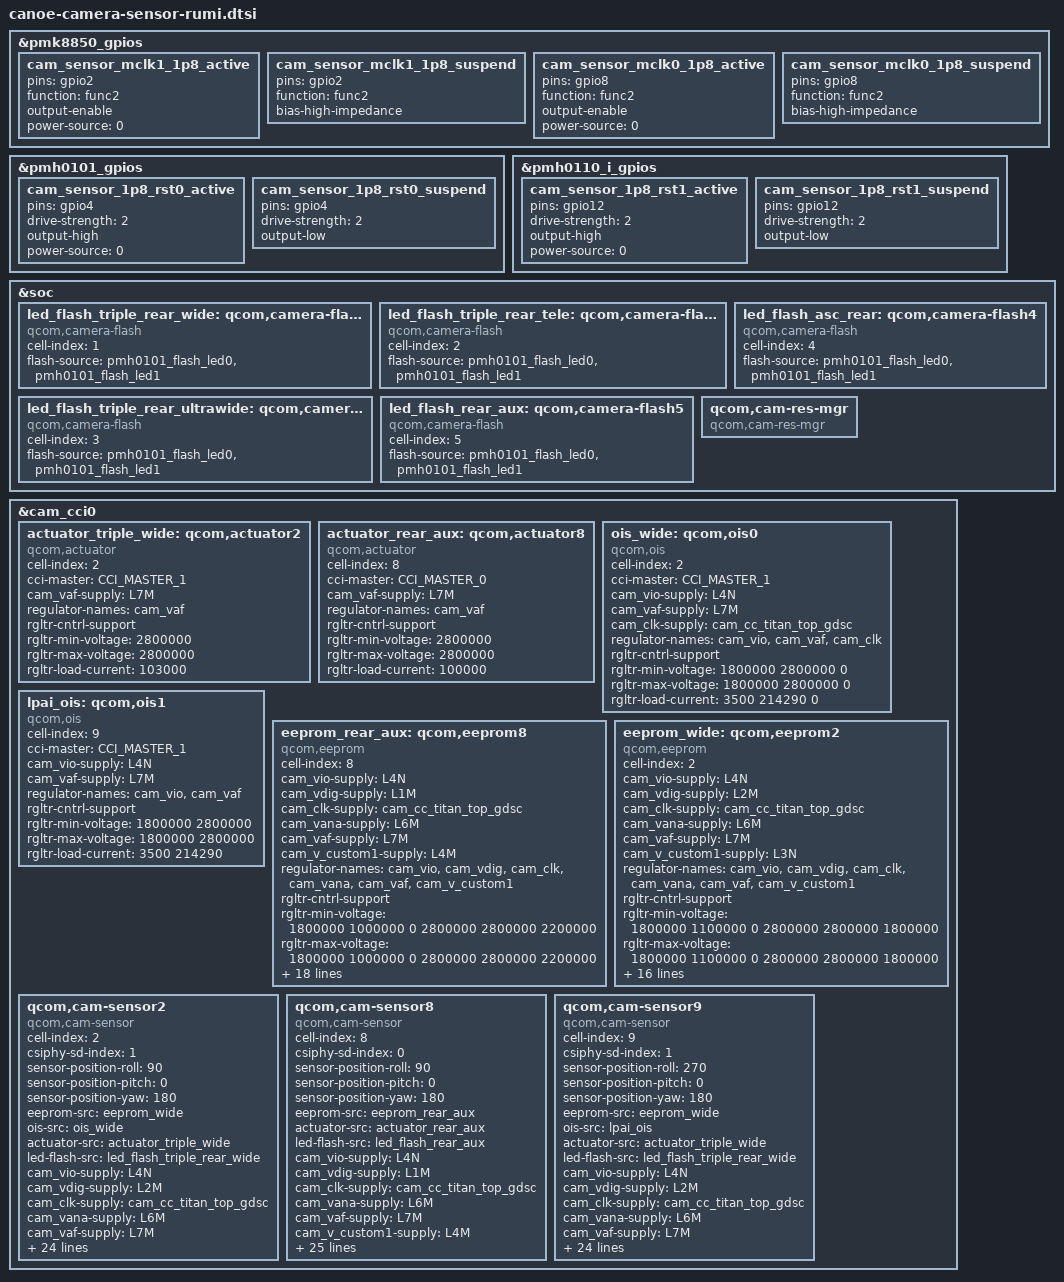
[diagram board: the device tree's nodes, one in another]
// SPDX-License-Identifier: BSD-3-Clause
/*
 * Copyright (c) 2024 Qualcomm Innovation Center, Inc. All rights reserved.
 */

#include <dt-bindings/msm-camera.h>

&pmk8850_gpios {
	cam_sensor_mclk1_1p8_active: cam_sensor_mclk1_1p8_active {
			pins = "gpio2";
			function = "func2";
			output-enable;
			power-source = <0>; /* 1.8 V */
	};

	cam_sensor_mclk1_1p8_suspend: cam_sensor_mclk1_1p8_suspend {
			pins = "gpio2";
			function = "func2";
			bias-high-impedance;
	};

	cam_sensor_mclk0_1p8_active: cam_sensor_mclk0_1p8_active {
			pins = "gpio8";
			function = "func2";
			output-enable;
			power-source = <0>; /* 1.8 V */
	};

	cam_sensor_mclk0_1p8_suspend: cam_sensor_mclk0_1p8_suspend {
			pins = "gpio8";
			function = "func2";
			bias-high-impedance;
	};
};

&pmh0101_gpios {
	cam_sensor_1p8_rst0_active: cam_sensor_1p8_rst0_active {
			pins = "gpio4";
			drive-strength = <2>;
			output-high;
			power-source = <0>; /* 1.8 V */
	};

	cam_sensor_1p8_rst0_suspend: cam_sensor_1p8_rst0_suspend {
			pins = "gpio4";
			drive-strength = <2>;
			output-low;
	};
};

&pmh0110_i_gpios {
	cam_sensor_1p8_rst1_active: cam_sensor_1p8_rst1_active {
			pins = "gpio12";
			drive-strength = <2>;
			output-high;
			power-source = <0>; /* 1.8 V */
	};

	cam_sensor_1p8_rst1_suspend: cam_sensor_1p8_rst1_suspend {
			pins = "gpio12";
			drive-strength = <2>;
			output-low;
	};
};

&soc {
	led_flash_triple_rear_wide: qcom,camera-flash1 {
		cell-index = <1>;
		compatible = "qcom,camera-flash";
		flash-source = <&pmh0101_flash_led0 &pmh0101_flash_led1>;
		status = "ok";
	};

	led_flash_triple_rear_tele: qcom,camera-flash2 {
		cell-index = <2>;
		compatible = "qcom,camera-flash";
		flash-source = <&pmh0101_flash_led0 &pmh0101_flash_led1>;
		status = "ok";
	};

	led_flash_triple_rear_ultrawide: qcom,camera-flash3 {
		cell-index = <3>;
		compatible = "qcom,camera-flash";
		flash-source = <&pmh0101_flash_led0 &pmh0101_flash_led1>;
		status = "ok";
	};

	led_flash_asc_rear: qcom,camera-flash4 {
		cell-index = <4>;
		compatible = "qcom,camera-flash";
		flash-source = <&pmh0101_flash_led0 &pmh0101_flash_led1>;
		status = "ok";
	};

	led_flash_rear_aux: qcom,camera-flash5 {
		cell-index = <5>;
		compatible = "qcom,camera-flash";
		flash-source = <&pmh0101_flash_led0 &pmh0101_flash_led1>;
		status = "ok";
	};

	qcom,cam-res-mgr {
		compatible = "qcom,cam-res-mgr";
		status = "ok";
	};
};

&cam_cci0 {

	actuator_triple_wide: qcom,actuator2 {
		cell-index = <2>;
		compatible = "qcom,actuator";
		cci-master = <CCI_MASTER_1>;
		cam_vaf-supply = <&L7M>;
		regulator-names = "cam_vaf";
		rgltr-cntrl-support;
		rgltr-min-voltage = <2800000>;
		rgltr-max-voltage = <2800000>;
		rgltr-load-current = <103000>;
		status = "ok";
	};

	actuator_rear_aux: qcom,actuator8 {
		cell-index = <8>;
		compatible = "qcom,actuator";
		cci-master = <CCI_MASTER_0>;
		cam_vaf-supply = <&L7M>;
		regulator-names = "cam_vaf";
		rgltr-cntrl-support;
		rgltr-min-voltage = <2800000>;
		rgltr-max-voltage = <2800000>;
		rgltr-load-current = <100000>;
		status = "ok";
	};

	ois_wide: qcom,ois0 {
		cell-index = <2>;
		compatible = "qcom,ois";
		cci-master = <CCI_MASTER_1>;
		cam_vio-supply = <&L4N>;
		cam_vaf-supply = <&L7M>;
		cam_clk-supply = <&cam_cc_titan_top_gdsc>;
		regulator-names = "cam_vio","cam_vaf", "cam_clk";
		rgltr-cntrl-support;
		rgltr-min-voltage = <1800000 2800000 0>;
		rgltr-max-voltage = <1800000 2800000 0>;
		rgltr-load-current = <3500 214290 0>;
		status = "ok";
	};

	lpai_ois: qcom,ois1 {
		cell-index = <9>;
		compatible = "qcom,ois";
		cci-master = <CCI_MASTER_1>;
		cam_vio-supply = <&L4N>;
		cam_vaf-supply = <&L7M>;
		regulator-names = "cam_vio","cam_vaf";
		rgltr-cntrl-support;
		rgltr-min-voltage = <1800000 2800000>;
		rgltr-max-voltage = <1800000 2800000>;
		rgltr-load-current = <3500 214290>;
		status = "ok";
	};

	eeprom_rear_aux: qcom,eeprom8 {
		cell-index = <8>;
		compatible = "qcom,eeprom";
		cam_vio-supply = <&L4N>;
		cam_vdig-supply = <&L1M>;
		cam_clk-supply = <&cam_cc_titan_top_gdsc>;
		cam_vana-supply = <&L6M>;
		cam_vaf-supply = <&L7M>;
		cam_v_custom1-supply = <&L4M>;
		regulator-names = "cam_vio", "cam_vdig", "cam_clk", "cam_vana",
			"cam_vaf", "cam_v_custom1";
		rgltr-cntrl-support;
		rgltr-min-voltage = <1800000 1000000 0 2800000 2800000 2200000>;
		rgltr-max-voltage = <1800000 1000000 0 2800000 2800000 2200000>;
		rgltr-load-current = <4280 815060 0 114500 100000 127100>;
		gpio-no-mux = <0>;
		pinctrl-names = "cam_default", "cam_suspend";
		pinctrl-0 = <&cam_sensor_test_mclk0_active
				 &cam_sensor_active_rst0>;
		pinctrl-1 = <&cam_sensor_test_mclk0_suspend
				 &cam_sensor_suspend_rst0>;
		gpios = <&tlmm 89 0>,
			<&tlmm 4 0>;
		gpio-reset = <1>;
		gpio-req-tbl-num = <0 1>;
		gpio-req-tbl-flags = <1 0>;
		gpio-req-tbl-label = "CAMIF_MCLK0",
					"CAM_RESET0_1P8";
		cci-master = <CCI_MASTER_0>;
		clocks = <&cambistmclkcc CAM_BIST_MCLK_CC_MCLK0_CLK>;
		clock-names = "cam_clk";
		clock-cntl-level = "nominal";
		clock-rates = <24000000>;
		status = "ok";
	};

	eeprom_wide: qcom,eeprom2 {
		cell-index = <2>;
		compatible = "qcom,eeprom";
		cam_vio-supply = <&L4N>;
		cam_vdig-supply = <&L2M>;
		cam_clk-supply = <&cam_cc_titan_top_gdsc>;
		cam_vana-supply = <&L6M>;
		cam_vaf-supply = <&L7M>;
		cam_v_custom1-supply = <&L3N>;
		regulator-names = "cam_vio", "cam_vdig", "cam_clk", "cam_vana",
			"cam_vaf", "cam_v_custom1";
		rgltr-cntrl-support;
		rgltr-min-voltage = <1800000 1100000 0 2800000 2800000 1800000>;
		rgltr-max-voltage = <1800000 1100000 0 2800000 2800000 1800000>;
		rgltr-load-current = <3500 913200 0 91430 103000 63100>;
		gpio-no-mux = <0>;
		pinctrl-names = "cam_default", "cam_suspend";
		pinctrl-0 = <&cam_sensor_mclk1_active
				&cam_sensor_active_rst1>;
		pinctrl-1 = <&cam_sensor_mclk1_suspend
				&cam_sensor_suspend_rst1>;
		gpios = <&tlmm 15 0>;
		gpio-reset = <0>;
		gpio-req-tbl-num = <0>;
		gpio-req-tbl-flags = <0>;
		gpio-req-tbl-label = "CAM_RESET1_1P8";
		cci-master = <CCI_MASTER_1>;
		clocks = <&rpmhcc RPMH_DIV_CLK1>;
		clock-names = "cam_clk";
		clock-cntl-level = "nominal";
		clock-rates = <24000000>;
		status = "ok";
	};

	qcom,cam-sensor2 {
		cell-index = <2>;
		compatible = "qcom,cam-sensor";
		csiphy-sd-index = <1>;
		sensor-position-roll = <90>;
		sensor-position-pitch = <0>;
		sensor-position-yaw = <180>;
		eeprom-src = <&eeprom_wide>;
		ois-src = <&ois_wide>;
		actuator-src = <&actuator_triple_wide>;
		led-flash-src = <&led_flash_triple_rear_wide>;
		cam_vio-supply = <&L4N>;
		cam_vdig-supply = <&L2M>;
		cam_clk-supply = <&cam_cc_titan_top_gdsc>;
		cam_vana-supply = <&L6M>;
		cam_vaf-supply = <&L7M>;
		cam_v_custom1-supply = <&L3N>;
		regulator-names = "cam_vio", "cam_vdig", "cam_clk", "cam_vana",
			"cam_vaf", "cam_v_custom1";
		rgltr-cntrl-support;
		rgltr-min-voltage = <1800000 1100000 0 2800000 2800000 1800000>;
		rgltr-max-voltage = <1800000 1100000 0 2800000 2800000 1800000>;
		rgltr-load-current = <3500 913200 0 91430 103000 63100>;
		gpio-no-mux = <0>;
		pinctrl-names = "cam_default", "cam_suspend";
		pinctrl-0 = <&cam_sensor_mclk1_active
				 &cam_sensor_active_rst1>;
		pinctrl-1 = <&cam_sensor_mclk1_suspend
				 &cam_sensor_suspend_rst1>;
		gpios = <&tlmm 15 0>;
		gpio-reset = <0>;
		gpio-req-tbl-num = <0>;
		gpio-req-tbl-flags = <0>;
		gpio-req-tbl-label = "CAM_RESET1_1P8";
		cci-master = <CCI_MASTER_1>;
		clocks = <&rpmhcc RPMH_DIV_CLK1>;
		clock-names = "cam_clk";
		clock-cntl-level = "nominal";
		clock-rates = <24000000>;
		status = "ok";
	};

	qcom,cam-sensor8 {
		cell-index = <8>;
		compatible = "qcom,cam-sensor";
		csiphy-sd-index = <0>;
		sensor-position-roll = <90>;
		sensor-position-pitch = <0>;
		sensor-position-yaw = <180>;
		eeprom-src = <&eeprom_rear_aux>;
		actuator-src = <&actuator_rear_aux>;
		led-flash-src = <&led_flash_rear_aux>;
		cam_vio-supply = <&L4N>;
		cam_vdig-supply = <&L1M>;
		cam_clk-supply = <&cam_cc_titan_top_gdsc>;
		cam_vana-supply = <&L6M>;
		cam_vaf-supply = <&L7M>;
		cam_v_custom1-supply = <&L4M>;
		regulator-names = "cam_vio", "cam_vdig", "cam_clk", "cam_vana",
			"cam_vaf", "cam_v_custom1";
		rgltr-cntrl-support;
		rgltr-min-voltage = <1800000 1000000 0 2800000 2800000 2200000>;
		rgltr-max-voltage = <1800000 1000000 0 2800000 2800000 2200000>;
		rgltr-load-current = <4280 815060 0 114500 100000 127100>;
		gpio-no-mux = <0>;
		pinctrl-names = "cam_default", "cam_suspend";
		pinctrl-0 = <&cam_sensor_test_mclk0_active
				 &cam_sensor_active_rst0>;
		pinctrl-1 = <&cam_sensor_test_mclk0_suspend
				 &cam_sensor_suspend_rst0>;
		gpios = <&tlmm 89 0>,
			<&tlmm 4 0>;
		gpio-reset = <1>;
		gpio-req-tbl-num = <0 1>;
		gpio-req-tbl-flags = <1 0>;
		gpio-req-tbl-label = "CAMIF_MCLK0",
					"CAM_RESET0_1P8";
		cci-master = <CCI_MASTER_0>;
		clocks = <&cambistmclkcc CAM_BIST_MCLK_CC_MCLK0_CLK>;
		clock-names = "cam_clk";
		clock-cntl-level = "nominal";
		clock-rates = <24000000>;
		status = "ok";
	};

	qcom,cam-sensor9 {
		cell-index = <9>;
		compatible = "qcom,cam-sensor";
		csiphy-sd-index = <1>;
		sensor-position-roll = <270>;
		sensor-position-pitch = <0>;
		sensor-position-yaw = <180>;
		eeprom-src = <&eeprom_wide>;
		ois-src = <&lpai_ois>;
		actuator-src = <&actuator_triple_wide>;
		led-flash-src = <&led_flash_triple_rear_wide>;
		cam_vio-supply = <&L4N>;
		cam_vdig-supply = <&L2M>;
		cam_clk-supply = <&cam_cc_titan_top_gdsc>;
		cam_vana-supply = <&L6M>;
		cam_vaf-supply = <&L7M>;
		cam_v_custom1-supply = <&L3N>;
		regulator-names = "cam_vio", "cam_vdig", "cam_clk", "cam_vana",
			"cam_vaf", "cam_v_custom1";
		rgltr-cntrl-support;
		rgltr-min-voltage = <1800000 1100000 0 2800000 2800000 1800000>;
		rgltr-max-voltage = <1800000 1100000 0 2800000 2800000 1800000>;
		rgltr-load-current = <3500 913200 0 91430 103000 63100>;
		gpio-no-mux = <0>;
		pinctrl-names = "cam_default", "cam_suspend";
		pinctrl-0 = <&cam_sensor_mclk1_active
				 &cam_sensor_active_rst1>;
		pinctrl-1 = <&cam_sensor_mclk1_suspend
				 &cam_sensor_suspend_rst1>;
		gpios = <&tlmm 15 0>;
		gpio-reset = <0>;
		gpio-req-tbl-num = <0>;
		gpio-req-tbl-flags = <0>;
		gpio-req-tbl-label = "CAM_RESET1_1P8";
		cci-master = <CCI_MASTER_1>;
		clocks = <&rpmhcc RPMH_DIV_CLK1>;
		clock-names = "cam_clk";
		clock-cntl-level = "nominal";
		clock-rates = <24000000>;
		status = "ok";
	};
};
